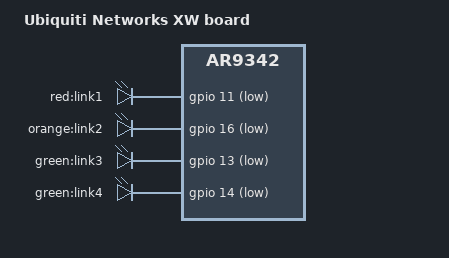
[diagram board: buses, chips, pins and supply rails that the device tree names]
// SPDX-License-Identifier: GPL-2.0-or-later OR MIT

#include "ar9342_ubnt_xw.dtsi"

#include <dt-bindings/gpio/gpio.h>
#include <dt-bindings/input/input.h>

/ {
	compatible = "ubnt,xw", "qca,ar9342";
	model = "Ubiquiti Networks XW board";

	aliases {
		led-boot = &led_link4;
		led-running = &led_link4;
		led-upgrade = &led_link4;
		led-failsafe = &led_link4;
		label-mac-device = &wmac;
	};

	leds {
		compatible = "gpio-leds";

		link1 {
			label = "red:link1";
			gpios = <&gpio 11 GPIO_ACTIVE_LOW>;
		};

		link2 {
			label = "orange:link2";
			gpios = <&gpio 16 GPIO_ACTIVE_LOW>;
		};

		link3 {
			label = "green:link3";
			gpios = <&gpio 13 GPIO_ACTIVE_LOW>;
		};

		led_link4: link4 {
			label = "green:link4";
			gpios = <&gpio 14 GPIO_ACTIVE_LOW>;
		};
	};
};
